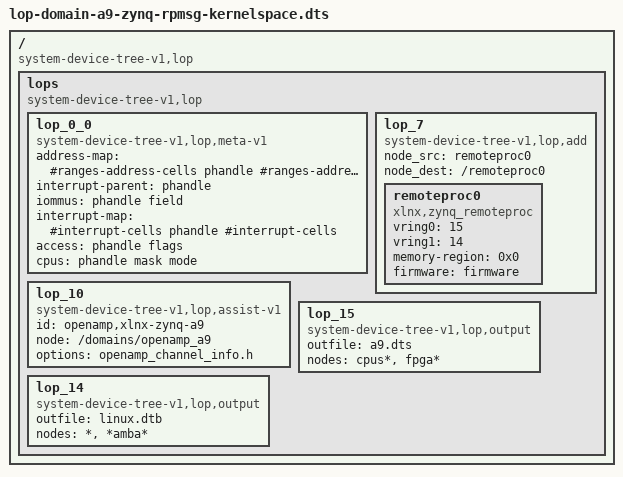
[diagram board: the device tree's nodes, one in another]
/*
 * Copyright (c) 2019,2020 Xilinx Inc. All rights reserved.
 *
 * Author:
 *       Bruce Ashfield <bruce.ashfield@xilinx.com>
 *
 * SPDX-License-Identifier: BSD-3-Clause
 */

/dts-v1/;

/ {
        compatible = "system-device-tree-v1,lop";
        lops {
                compatible = "system-device-tree-v1,lop";
                lop_0_0 {
                        compatible = "system-device-tree-v1,lop,meta-v1","phandle-desc-v1";
                        address-map = "#ranges-address-cells phandle #ranges-address-cells #ranges-size-cells";
                        interrupt-parent = "phandle";
                        iommus = "phandle field";
                        interrupt-map = "#interrupt-cells phandle #interrupt-cells";
                        access = "phandle flags";
                        cpus = "phandle mask mode";
                };
                lop_7 {
                        // node add
                        compatible = "system-device-tree-v1,lop,add";
                        node_src = "remoteproc0";
                        node_dest = "/remoteproc0";
                        remoteproc0 {
                            compatible = "xlnx,zynq_remoteproc";
			    vring0 = <15>;
			    vring1 = <14>;
                            memory-region = <0x0> ;
			    firmware = "firmware";
                        };
                  };
                  lop_10 {
                          // optionally execute a routine in a loaded module. If the routine
                          // isn't found, this is NOT a failure. Since we don't want to tightly
                          // couple these transforms and loaded modules
                          compatible = "system-device-tree-v1,lop,assist-v1";
                          id = "openamp,xlnx-zynq-a9";
                          node = "/domains/openamp_a9";
                          options = "openamp_channel_info.h";
                  };
                  
                  lop_15 {
                         compatible = "system-device-tree-v1,lop,output";
                         outfile = "a9.dts";
                         // * is "all nodes"
                         nodes =  "cpus*","fpga*";
                  };
                  lop_14 {
                         compatible = "system-device-tree-v1,lop,output";
                         outfile = "linux.dtb";
                         // * is "all nodes"
			 nodes =  "*", "*amba*";
                  };

        };
};
